# TM4C1294NCPDT register map
Vendor: Texas Instruments; File version: 2.2.0.295
CPU: CM4 r0p1, little endian, MPU, FPU, 3 interrupt priority bits
Registers are 32-bit, read-write, no defined reset value unless marked. A register's access mark holds for its fields unless they carry their own. Offsets are from the block's base; [hi:lo] are bit positions; {n}, {i} and the like mark numbered series; 'fields as' and 'values as' point back to an identical list.

## HIB — Hibernation module (HIB)
Base 0x400FC000
0x00 RTCC
  [31:0] VALUE — RTC Counter
0x04 RTCM0
  [31:0] VALUE — RTC Match 0
0x0C RTCLD
  [31:0] VALUE — RTC Load
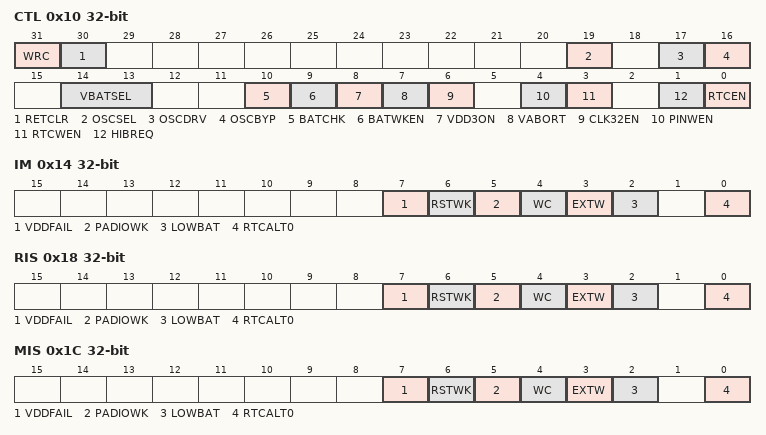
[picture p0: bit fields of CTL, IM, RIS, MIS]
0x10 CTL
  [31] WRC — Write Complete/Capable
  [30] RETCLR — GPIO Retention/Clear
  [19] OSCSEL — Oscillator Select
  [17] OSCDRV — Oscillator Drive Capability
  [16] OSCBYP — Oscillator Bypass
  [14:13] VBATSEL — Select for Low-Battery
    0=1_9V (1.9 Volts); 1=2_1V (2.1 Volts (default)); 2=2_3V (2.3 Volts); 3=2_5V (2.5 Volts)
  [10] BATCHK — Check Battery Status
  [9] BATWKEN — Wake on Low Battery
  [8] VDD3ON — VDD Powered
  [7] VABORT — Power Cut Abort Enable
  [6] CLK32EN — Clocking Enable
  [4] PINWEN — External Wake Pin Enable
  [3] RTCWEN — RTC Wake-up Enable
  [1] HIBREQ — Hibernation Request
  [0] RTCEN — RTC Timer Enable
0x14 IM
  [7] VDDFAIL — VDD Fail Interrupt Mask
  [6] RSTWK — Reset Pad I/O Wake-Up Interrupt
  [5] PADIOWK — Pad I/O Wake-Up Interrupt Mask
  [4] WC — External Write Complete/Capable
  [3] EXTW — External Wake-Up Interrupt Mask
  [2] LOWBAT — Low Battery Voltage Interrupt
  [0] RTCALT0 — RTC Alert 0 Interrupt Mask
0x18 RIS
  [7] VDDFAIL — VDD Fail Raw Interrupt Status
  [6] RSTWK — Reset Pad I/O Wake-Up Raw
  [5] PADIOWK — Pad I/O Wake-Up Raw Interrupt
  [4] WC — Write Complete/Capable Raw
  [3] EXTW — External Wake-Up Raw Interrupt
  [2] LOWBAT — Low Battery Voltage Raw
  [0] RTCALT0 — RTC Alert 0 Raw Interrupt Status
0x1C MIS
  [7] VDDFAIL — VDD Fail Interrupt Mask
  [6] RSTWK — Reset Pad I/O Wake-Up Interrupt
  [5] PADIOWK — Pad I/O Wake-Up Interrupt Mask
  [4] WC — Write Complete/Capable Masked
  [3] EXTW — External Wake-Up Masked
  [2] LOWBAT — Low Battery Voltage Masked
  [0] RTCALT0 — RTC Alert 0 Masked Interrupt
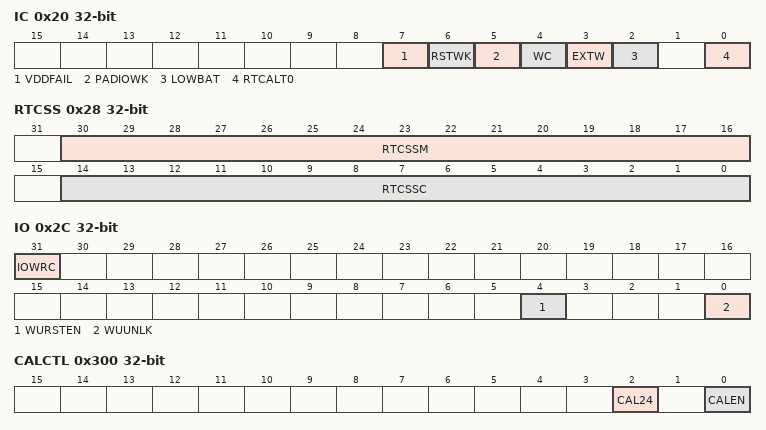
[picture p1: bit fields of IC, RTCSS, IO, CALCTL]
0x20 IC
  [7] VDDFAIL — VDD Fail Interrupt Clear
  [6] RSTWK — Reset Pad I/O Wake-Up Interrupt
  [5] PADIOWK — Pad I/O Wake-Up Interrupt Clear
  [4] WC — Write Complete/Capable Interrupt
  [3] EXTW — External Wake-Up Interrupt Clear
  [2] LOWBAT — Low Battery Voltage Interrupt
  [0] RTCALT0 — RTC Alert0 Masked Interrupt
0x24 RTCT
  [15:0] TRIM — RTC Trim Value
0x28 RTCSS
  [30:16] RTCSSM — RTC Sub Seconds Match
  [14:0] RTCSSC — RTC Sub Seconds Count
0x2C IO
  [31] IOWRC — I/O Write Complete
  [4] WURSTEN — Reset Wake Source Enable
  [0] WUUNLK — I/O Wake Pad Configuration
0x30 DATA
  [31:0] RTD — Hibernation Module NV Data
0x300 CALCTL
  [2] CAL24 — Calendar Mode
  [0] CALEN — RTC Calendar/Counter Mode Select
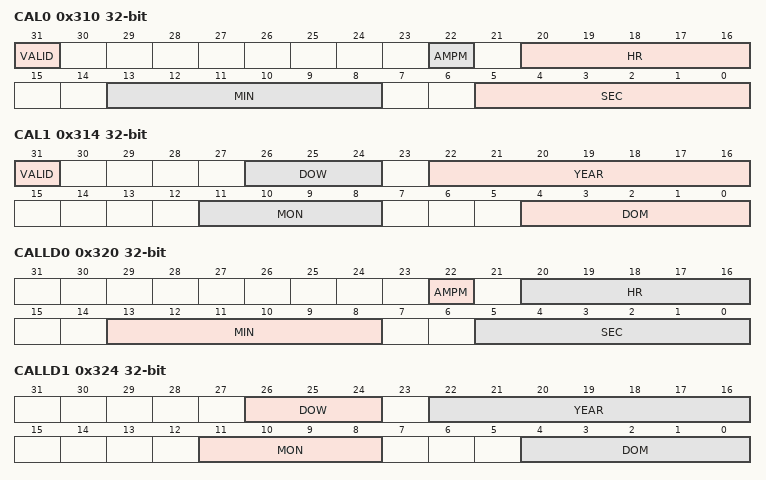
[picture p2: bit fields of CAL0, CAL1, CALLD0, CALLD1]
0x310 CAL0
  [31] VALID — Valid Calendar Load
  [22] AMPM — AM/PM Designation
  [20:16] HR — Hours
  [13:8] MIN — Minutes
  [5:0] SEC — Seconds
0x314 CAL1
  [31] VALID — Valid Calendar Load
  [26:24] DOW — Day of Week
  [22:16] YEAR — Year Value
  [11:8] MON — Month
  [4:0] DOM — Day of Month
0x320 CALLD0
  [22] AMPM — AM/PM Designation
  [20:16] HR — Hours
  [13:8] MIN — Minutes
  [5:0] SEC — Seconds
0x324 CALLD1
  [26:24] DOW — Day of Week
  [22:16] YEAR — Year Value
  [11:8] MON — Month
  [4:0] DOM — Day of Month
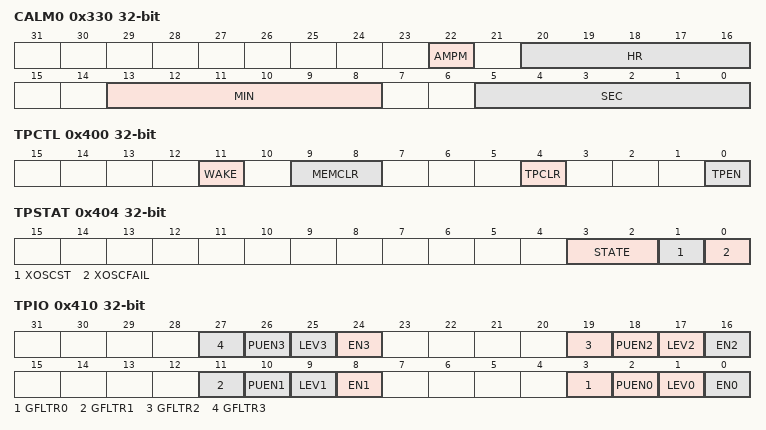
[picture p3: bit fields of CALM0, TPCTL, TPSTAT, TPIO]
0x330 CALM0
  fields as CALLD0
0x334 CALM1
  [4:0] DOM — Day of Month
0x360 LOCK
  [31:0] HIBLOCK — HIbernate Lock
0x400 TPCTL
  [11] WAKE — Wake from Hibernate on a Tamper
  [9:8] MEMCLR — HIB Memory Clear on Tamper Event
    0=NONE (Do not Clear HIB memory on); 1=LOW32 (Clear Lower 32 Bytes of HIB); 2=HIGH32 (Clear upper 32 Bytes of HIB); 3=ALL (Clear all HIB memory on tamper)
  [4] TPCLR — Tamper Event Clear
  [0] TPEN — Tamper Module Enable
0x404 TPSTAT
  [3:2] STATE — Tamper Module Status
    0=DISABLED (Tamper disabled); 1=CONFIGED (Tamper configured); 2=ERROR (Tamper pin event occurred)
  [1] XOSCST — External Oscillator Status
  [0] XOSCFAIL — External Oscillator Failure
0x410 TPIO
  [8n+3] GFLTR{n} (n=0..3) — TMPR{n} Glitch Filtering
  [8n+2] PUEN{n} (n=0..3) — TMPR{n} Internal Weak Pull-up
  [8n+1] LEV{n} (n=0..3) — TMPR{n} Trigger Level
  [24] EN3 — TMPR3 Enable
  [16] EN2 — TMPR2 Enable
  [8] EN1 — TMPR1Enable
  [0] EN0 — TMPR0 Enable
0x4E0 TPLOG0
  [31:0] TIME — Tamper Log Calendar Information
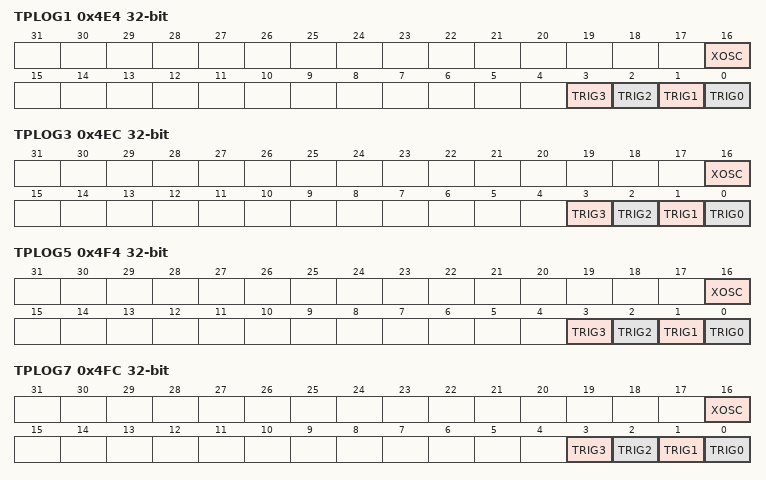
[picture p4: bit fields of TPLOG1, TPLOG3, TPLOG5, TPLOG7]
0x4E4 TPLOG1
  [16] XOSC — Status of external 32
  [n] TRIG{n} (n=0..3) — Status of TMPR[{n}] Trigger
0x4E8 TPLOG2
  [31:0] TIME — Tamper Log Calendar Information
0x4EC TPLOG3
  fields as TPLOG1
0x4F0 TPLOG4
  [31:0] TIME — Tamper Log Calendar Information
0x4F4 TPLOG5
  fields as TPLOG1
0x4F8 TPLOG6
  [31:0] TIME — Tamper Log Calendar Information
0x4FC TPLOG7
  fields as TPLOG1
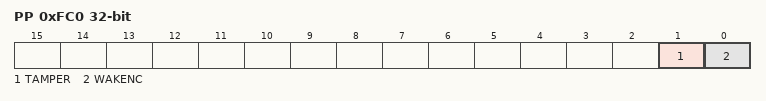
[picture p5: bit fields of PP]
0xFC0 PP
  [1] TAMPER — Tamper Pin Presence
  [0] WAKENC — Wake Pin Presence
0xFC8 CC
  [0] SYSCLKEN — RTCOSC to System Clock Enable
